# camera register map
Vendor: Texas Instruments
Peripheral module from a debugger description file (folder cc32).
Registers are 32-bit, read-write, no defined reset value unless marked. A register's access mark holds for its fields unless they carry their own. Offsets are as the file gives them; lines under a group give offsets from that group; [hi:lo] are bit positions; {n}, {i} and the like mark numbered series; 'fields as' and 'values as' point back to an identical list; <NAME> marks a mode.

## camera
0x00 CC_REVISION — This register contains the IP revision code ( Parallel Mode)
  [7:0] REV — IP revision [7:4] Major revision [3:0] Minor revision Examples: 0x10 for 1.0 0x21 for 2.1
0x10 CC_SYSCONFIG — This register controls the various parameters of the OCP interface (CCP and Parallel Mode)
  [4:3] S_IDLE_MODE — Slave interface power management req/ack control """00"" Force-idle. An idle request is acknoledged unconditionally" """01"" No-idle. An idle request is never acknowledged" """10"" reserved (Smart-idle not implemented)"
0x14 CC_SYSSTATUS access not given — This register provides status information about the module excluding the interrupt status information (CCP and Parallel Mode)
0x18 CC_IRQSTATUS access not given — The interrupt status regroups all the status of the module internal events that can generate an interrupt (CCP & Parallel Mode)
0x1C CC_IRQENABLE access not given — The interrupt enable register allows to enable/disable the module internal sources of interrupt on an event-by-event basis (CCP & Parallel Mode)
0x40 CC_CTRL — This register controls the various parameters of the Camera Core block (CCP & Parallel Mode)
  [3:1] PAR_MODE — Sets the Protocol Mode of the Camera Core module in parallel mode (when CCP_MODE = 0) """000"" Parallel NOBT 8-bit" """001"" Parallel NOBT 10-bit" """010"" Parallel NOBT 12-bit" """011"" reserved" """100"" Parallet BT 8-bit" """101"" Parallel BT 10-bit" """110"" reserved" """111"" FIFO test mode. Refer to Table 12 - FIFO Write and Read access"
0x44 CC_CTRL_DMA — This register controls the DMA interface of the Camera Core block (CCP & Parallel Mode)
  [6:0] FIFO_THRESHOLD — Sets the threshold of the FIFO the assertion of the dmarequest line takes place when the threshold is reached. """0000000"" threshold set to 1" """0000001"" threshold set to 2" """1111111"" threshold set to 128"
0x48 CC_CTRL_XCLK — This register control the value of the clock divisor used to generate the external clock (Parallel Mode)
  [4:0] XCLK_DIV — Sets the clock divisor value for CAM_XCLK generation. based on CAM_MCK (value of CAM_MCLK is 96MHz) """00000"" CAM_XCLK Stable Low Level" Divider not enabled """00001"" CAM_XCLK Stable High Level" Divider not enabled from 2 to 30 CAM_XCLK = CAM_MCLK / XCLK_DIV """11111"" Bypass - CAM_XCLK = CAM_MCLK"
0x4C CC_FIFO_DATA access not given — This register allows to write to the FIFO and read from the FIFO (CCP & Parallel Mode)
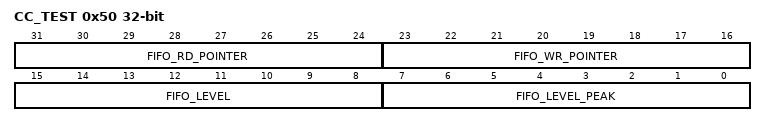
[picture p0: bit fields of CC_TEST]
0x50 CC_TEST — This register shows the status of some important variables of the camera core module (CCP & Parallel Mode)
  [31:24] FIFO_RD_POINTER — FIFO READ Pointer This field shows the value of the FIFO read pointer Expected value ranges from 0 to 127
  [23:16] FIFO_WR_POINTER — FIFO WRITE pointer This field shows the value of the FIFO write pointer Expected value ranges from 0 to 127
  [15:8] FIFO_LEVEL — FIFO level (how many 32-bit words the FIFO contains) This field shows the value of the FIFO level and can assume values from 0 to 128
  [7:0] FIFO_LEVEL_PEAK — FIFO level peak This field shows the max value of the FIFO level and can assume values from 0 to 128
0x54 CC_GEN_PAR — This register shows the values of the generic parameters of the module ****************************************************************************
  [2:0] CC_FIFO_DEPTH — Camera Core FIFO DEPTH generic parameter
